# CPRMAN register map
File version: 1
BCM2711 clock manager: the PWM clock's control and divisor
Registers are read-write, no defined reset value unless marked. A register's access mark holds for its fields unless they carry their own. Offsets are from the block's base; lines under a group give offsets from that group; [hi:lo] are bit positions; {n}, {i} and the like mark numbered series; 'fields as' and 'values as' point back to an identical list; <NAME> marks a mode.

## Memory map
0x00000000 CPRMAN size 0xA8

## CPRMAN
Base 0x00000000
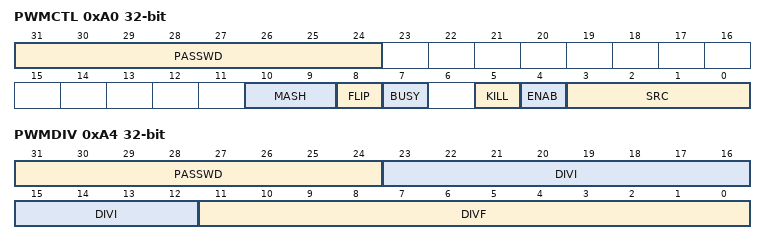
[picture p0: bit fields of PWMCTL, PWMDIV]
0xA0 PWMCTL — The PWM clock's control, in Table 99's format (unverified for this clock): its source, enable and MASH stages; a write takes effect only with PASSWD 0x5a
  [31:24] PASSWD wo — The clock manager's password, 0x5a, with every write
  [10:9] MASH — 0 integer division, 1 to 3 that many MASH stages; not to be changed while BUSY is 1
  [8] FLIP — 1 inverts the output, for test and debug only
  [7] BUSY ro — 1 while the clock generator runs
  [5] KILL — 1 stops and resets the clock generator, for test and debug only
  [4] ENAB — 1 requests the clock to start, 0 to stop after its current cycle
  [3:0] SRC — Clock source; 8 to 15 are GND too; not to be changed while BUSY is 1
    0=GND; 1=OSCILLATOR; 2=TESTDEBUG0; 3=TESTDEBUG1; 4=PLLA_PER; 5=PLLC_PER; 6=PLLD_PER; 7=HDMI_AUXILIARY
0xA4 PWMDIV — The PWM clock's divisor, in Table 100's format (unverified for this clock); a write takes effect only with PASSWD 0x5a
  [31:24] PASSWD wo — The clock manager's password, 0x5a, with every write
  [23:12] DIVI — The divisor's integer part, at least the minimum the MASH setting needs
  [11:0] DIVF — The divisor's fractional part

## Notices in the file
Copyright (c) 2026, Stanislav Sedov <stas@deglitch.com>
SPDX-License-Identifier: BSD-2-Clause
